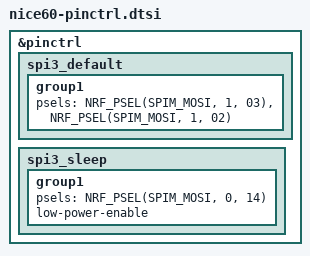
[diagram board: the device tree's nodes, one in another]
&pinctrl {
    spi3_default: spi3_default {
        group1 {
            psels = <NRF_PSEL(SPIM_MOSI, 1, 03)>,
            <NRF_PSEL(SPIM_MOSI, 1, 02)>;
        };
    };

    spi3_sleep: spi3_sleep {
        group1 {
            psels = <NRF_PSEL(SPIM_MOSI, 0, 14)>;
            low-power-enable;
        };
    };
};
